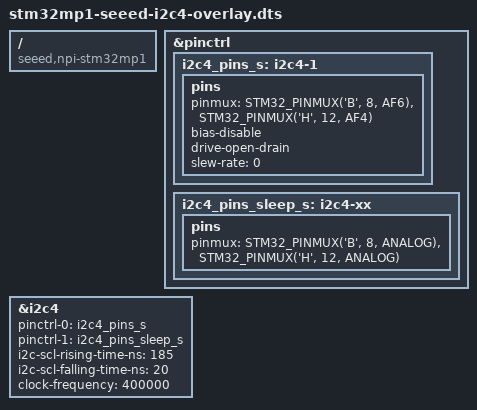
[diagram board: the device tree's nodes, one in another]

/*
 * Device tree overlay for i2c4
 */


#include "dt-bindings/gpio/gpio.h"
#include "dt-bindings/pinctrl/stm32-pinfunc.h"

/dts-v1/;
/plugin/;

/ {
     compatible = "seeed,npi-stm32mp1", "st,stm32mp157";
    fragment@0 {
        target = <&pinctrl>;
        __overlay__ {
                       i2c4_pins_s: i2c4-1 {
                               pins {
                                       pinmux = <STM32_PINMUX('B', 8, AF6)>, /* I2C4_SCL */
                                                <STM32_PINMUX('H', 12, AF4)>; /* I2C4_SDA */
                                       bias-disable;                 /*pull disable*/
                                       drive-open-drain;             /*open drain enable*/
                                       slew-rate = <0>;            
                               };
                       };
                       i2c4_pins_sleep_s: i2c4-xx {
                               pins {
                                       pinmux = <STM32_PINMUX('B', 8, ANALOG)>, /* I2C4_SCL */
                                                <STM32_PINMUX('H', 12, ANALOG)>; /* I2C4_SCL */                                   
                               };
                       };
        };
    };
    fragment@1 {
        target = <&i2c4>;
        __overlay__ {
            pinctrl-names = "default", "sleep";
            pinctrl-0 = <&i2c4_pins_s>;
            pinctrl-1 = <&i2c4_pins_sleep_s>;
            i2c-scl-rising-time-ns = <185>;
            i2c-scl-falling-time-ns = <20>;
	    clock-frequency = <400000>;
            status = "okay";
            /delete-property/dmas;
            /delete-property/dma-names;
        };
    };
};

